AUTOSAR XML (schema 4-2-2)
package /AUTOSAR/Components
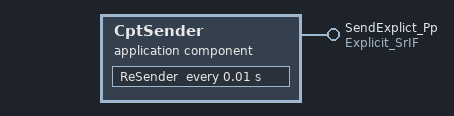
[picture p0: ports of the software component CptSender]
  application sw component type CptSender
    provide port SendExplict_Pp: provided-interface=Explicit_SrIF
    behavior IbSender
      timing event timingEvent_10: start-on-event=ReSender, period=0.01
      runnable ReSender: symbol=AppSender_Func
        data-send-points:
          access DspStruct: accessed-variable=SendExplict_Pp.structDE
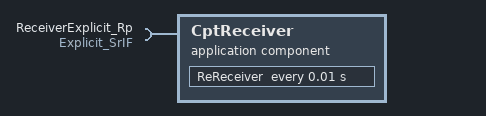
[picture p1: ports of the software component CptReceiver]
  application sw component type CptReceiver
    require port ReceiverExplicit_Rp: nonqueued-receiver-com-spec{data-element=structDE, external-replacement=structDE, uses-end-to-end-protection=true, init-value=fields=[0, 0, 0]}, required-interface=Explicit_SrIF
    behavior IbReceiver
      timing event timingEvent_10: start-on-event=ReReceiver, period=0.01
      runnable ReReceiver: symbol=AppReceiver_Func
        data-receive-point-by-arguments:
          access DrpbaStruct: accessed-variable=ReceiverExplicit_Rp.structDE
